# SF32LB52x register map
File version: 1.0
CPU: CM33 r0p1, little endian, MPU, FPU, 3 interrupt priority bits
Registers are 32-bit, read-write, reset 0x0 unless marked. A register's access mark holds for its fields unless they carry their own. Offsets are from the block's base; [hi:lo] are bit positions; {n}, {i} and the like mark numbered series; 'fields as' and 'values as' point back to an identical list.

## PDM1 — Pulse Density Modulation
Base 0x5009A000
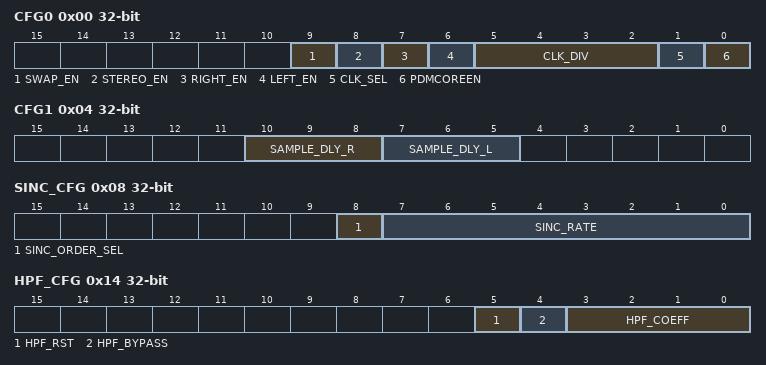
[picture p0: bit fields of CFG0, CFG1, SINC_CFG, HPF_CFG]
0x00 CFG0
  [9] SWAP_EN — 1: Swap right channel and left channel pdm data; 0: Not swap right channel and left channel pdm data
  [8] STEREO_EN — 1:Enable double channels pdm data sampling; 0: Disable double channels pdm data sampling
  [7] RIGHT_EN — 1: Enable right channel pdm data sampling; 0: Disable right channel pdm data sampling
  [6] LEFT_EN — 1: Enable left channel pdm data sampling; 0: Disable left channel pdm data sampling
  [5:2] CLK_DIV — Clock frequency division ratio of 3.072MHz or 9.6MHz according to register clk_sel
  [1] CLK_SEL — 1:Clk select dll 3.072MHz; 0: Clk selct xtal 9.6MHz
  [0] PDMCOREEN — 1:Enable pdm module; 0: Disable pdm module
0x04 CFG1
  [10:8] SAMPLE_DLY_R — The number of delay dff before the right data stream in processing
  [7:5] SAMPLE_DLY_L — The number of delay dff before the left data stream in processing
0x08 SINC_CFG
  [8] SINC_ORDER_SEL — 1:select four differentiators in sinc filter; 0:select three differentiators in sinc filter
  [7:0] SINC_RATE — dowmsampling rate of sinc filter
0x14 HPF_CFG
  [5] HPF_RST — 1:high-pass filter normal operation ; 0:reset high-pass filter
  [4] HPF_BYPASS — 1:bypass-high pass filter ; 0: enable high-pass filter
  [3:0] HPF_COEFF — coefficient of high-pass filter
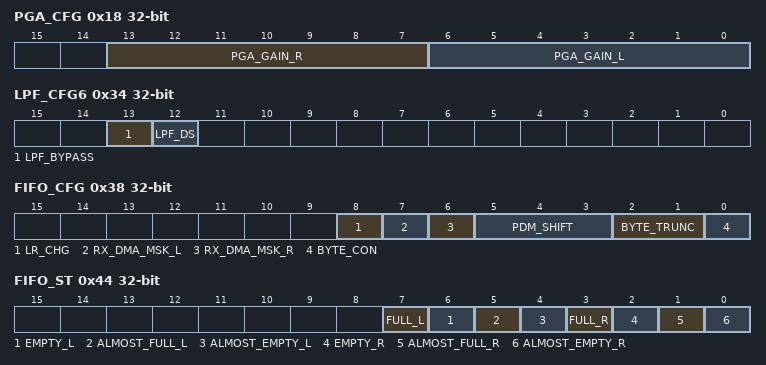
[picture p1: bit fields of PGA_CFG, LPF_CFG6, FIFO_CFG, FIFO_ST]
0x18 PGA_CFG
  [13:7] PGA_GAIN_R — right channel gain control , the range is -15dB~45dB. Resolution is 0.5dB/LSB
  [6:0] PGA_GAIN_L — left channel gain control , the range is -15dB~45dB. Resolution is 0.5dB/LSB
0x34 LPF_CFG6
  [13] LPF_BYPASS — 1:bypass low-pass filter ; 0: enable low-pass filter
  [12] LPF_DS — 1:downsampling rate of low pass filter is two;0:No downsampling of low pass filter
0x38 FIFO_CFG
  [8] LR_CHG — 1:exchange storage location of left and right channel; 0: don't exchange storage location of left and right channel
  [7] RX_DMA_MSK_L — 1:disable left channel dma request; 0: enable left channel dma request
  [6] RX_DMA_MSK_R — 1:disable right channel dma request; 0: enable right channel dma request
  [5:3] PDM_SHIFT — the number of data left shift for higher data accuracy
  [2:1] BYTE_TRUNC — 1: 16bits output ; 0: 24bits output ;2: 8bits output ; 3: 32bits output
  [0] BYTE_CON — 1: combine left channel and right channel; 0: not combine left channel and right channel
0x44 FIFO_ST
  [7] FULL_L — 1 indicates left channel fifo is full
  [6] EMPTY_L — 1 indicates left channel fifo is empty
  [5] ALMOST_FULL_L — 1 indicates left channel fifo is less than two full
  [4] ALMOST_EMPTY_L — 1 indicates left channel fifo is less than two datas left
  [3] FULL_R — 1 indicates right channel fifo is full
  [2] EMPTY_R — 1 indicates right channel fifo is empty
  [1] ALMOST_FULL_R — 1 indicates right channel fifo is less than two full
  [0] ALMOST_EMPTY_R — 1 indicates right channel fifo is less than two datas left
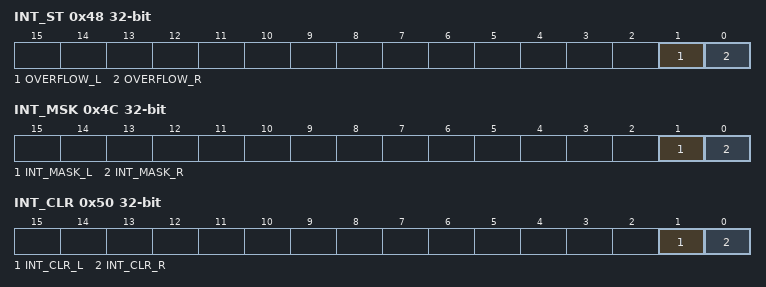
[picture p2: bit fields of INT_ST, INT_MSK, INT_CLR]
0x48 INT_ST
  [1] OVERFLOW_L — 1 indicates left channel fifo has already overflowed and as irq at same time
  [0] OVERFLOW_R — 1 indicates right channel fifo has already overflowed and as irq at same time
0x4C INT_MSK
  [1] INT_MASK_L — 1:disable left channel irq to system; 0: enable left channel irq to system
  [0] INT_MASK_R — 1:disable right channel irq to system; 0: enable right channel irq to system
0x50 INT_CLR
  [1] INT_CLR_L — clear left channel irq
  [0] INT_CLR_R — clear right channel irq

## LPSYS_PINMUX
Base 0x40003000
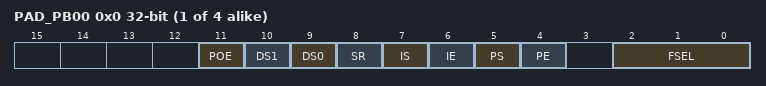
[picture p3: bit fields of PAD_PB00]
{0x0+4i} PAD_PB{i:02} (i=0..3)
  [11] POE — Reserved. Always set to logic LOW
  [10] DS1 — Drive Select 1. Used to select output drive strength
  [9] DS0 — Drive Select 0. Used to select output drive strength
  [8] SR — Slew Rate. Logic HIGH selects slow slew rate, logic LOW selects fast slew rate
  [7] IS — Input Select. Logic LOW selects CMOS input, logic HIGH selects Schmitt input
  [6] IE — Input Enable. Logic HIGH enables the input buffer
  [5] PS — Pull Select. Logic HIGH selects pull-up, logic LOW select pull-down
  [4] PE — Pull Enable. Logic HIGH enables week pull device
  [2:0] FSEL — Function Select

## LPSYS_CFG
Base 0x4000F000
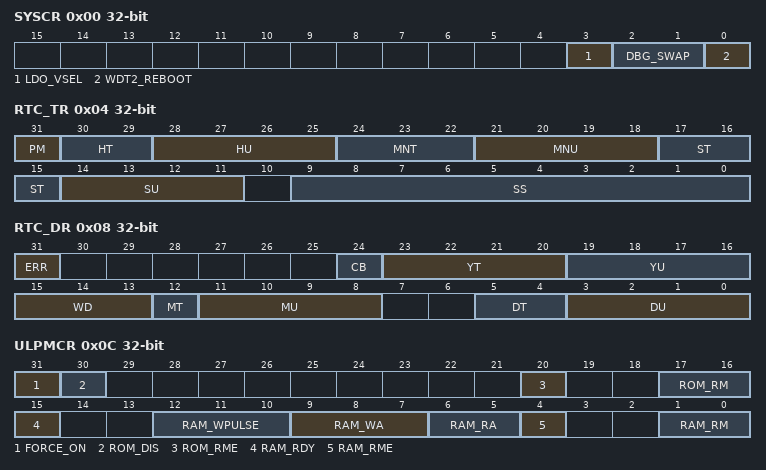
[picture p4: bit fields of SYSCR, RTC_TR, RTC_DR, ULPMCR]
0x00 SYSCR — System Configure Register
  [3] LDO_VSEL — select work mode 0: D 1: S
  [2:1] DBG_SWAP — reserved for debug
  [0] WDT2_REBOOT — If set to 1, WDT2 reset will reboot the whole chip
0x04 RTC_TR — Mirrored RTC Time Register
  [31] PM — AM/PM notation 0: AM 1: PM
  [30:29] HT — Hour tens in BCD format
  [28:25] HU — Hour units in BCD format
  [24:22] MNT — Minute tens in BCD format
  [21:18] MNU — Minute units in BCD format
  [17:15] ST — Second tens in BCD format
  [14:11] SU — Second units in BCD format
  [9:0] SS — Sub-second counter
0x08 RTC_DR — Mirrored RTC Date Register
  [31] ERR — reserved for debug
  [24] CB — Century flag
  [23:20] YT — Year tens in BCD format
  [19:16] YU — Year units in BCD format
  [15:13] WD — Week day units 000: forbidden 001: Monday ... 111: Sunday
  [12] MT — Month tens in BCD format
  [11:8] MU — Month units in BCD format
  [5:4] DT — Date tens in BCD format
  [3:0] DU — Date units in BCD format
0x0C ULPMCR — ULP Memory Control register
  [31] FORCE_ON — reserved for debug
  [30] ROM_DIS — reserved for debug
  [20] ROM_RME — reserved for debug
  [17:16] ROM_RM — reserved for debug
  [15] RAM_RDY — reserved for debug
  [12:10] RAM_WPULSE — reserved for debug
  [9:7] RAM_WA — reserved for debug
  [6:5] RAM_RA — reserved for debug
  [4] RAM_RME — reserved for debug
  [1:0] RAM_RM — reserved for debug
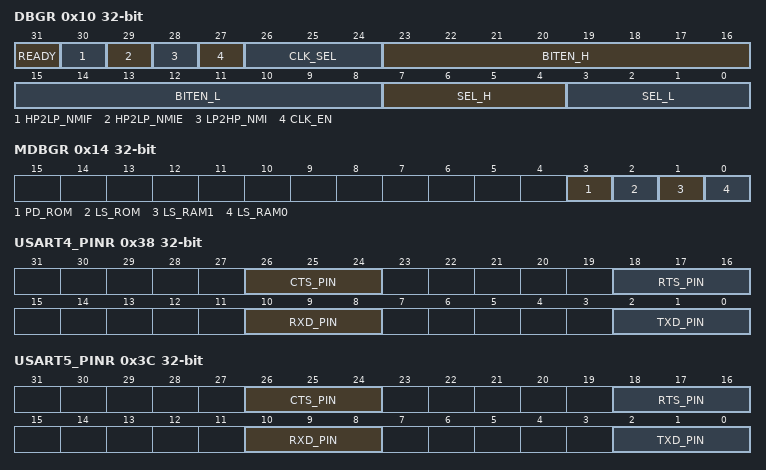
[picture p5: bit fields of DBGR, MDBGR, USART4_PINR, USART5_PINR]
0x10 DBGR — Debug Register
  [31] READY — reserved for debug
  [30] HP2LP_NMIF — HP2LP NMI interrupt flag
  [29] HP2LP_NMIE — HP2LP NMI interrupt enable
  [28] LP2HP_NMI — set 1 to send NMI interrupt to HCPU
  [27] CLK_EN — reserved for debug
  [26:24] CLK_SEL — reserved for debug
  [23:16] BITEN_H — reserved for debug
  [15:8] BITEN_L — reserved for debug
  [7:4] SEL_H — reserved for debug
  [3:0] SEL_L — reserved for debug
0x14 MDBGR — Memory Debug Register
  [3] PD_ROM — reserved for debug
  [2] LS_ROM — reserved for debug
  [1] LS_RAM1 — reserved for debug
  [0] LS_RAM0 — reserved for debug
0x38 USART4_PINR — USART4 Pin Register
  [26:24] CTS_PIN — Connect function pin to selected IO(PB). 0 to 3 for PB00 to PB03. Other values for floating.
  [18:16] RTS_PIN — Connect function pin to selected IO(PB). 0 to 3 for PB00 to PB03. Other values for floating.
  [10:8] RXD_PIN — Connect function pin to selected IO(PB). 0 to 3 for PB00 to PB03. Other values for floating.
  [2:0] TXD_PIN — Connect function pin to selected IO(PB). 0 to 3 for PB00 to PB03. Other values for floating.
0x3C USART5_PINR — USART5 Pin Register
  fields as USART4_PINR
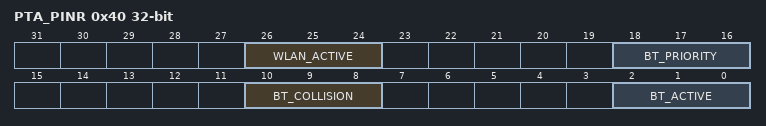
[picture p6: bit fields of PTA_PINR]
0x40 PTA_PINR — PTA Pin Register
  [26:24] WLAN_ACTIVE — Connect function pin to selected IO(PB). 0 to 3 for PB00 to PB03. Other values for floating.
  [18:16] BT_PRIORITY — Connect function pin to selected IO(PB). 0 to 3 for PB00 to PB03. Other values for floating.
  [10:8] BT_COLLISION — Connect function pin to selected IO(PB). 0 to 3 for PB00 to PB03. Other values for floating.
  [2:0] BT_ACTIVE — Connect function pin to selected IO(PB). 0 to 3 for PB00 to PB03. Other values for floating.
